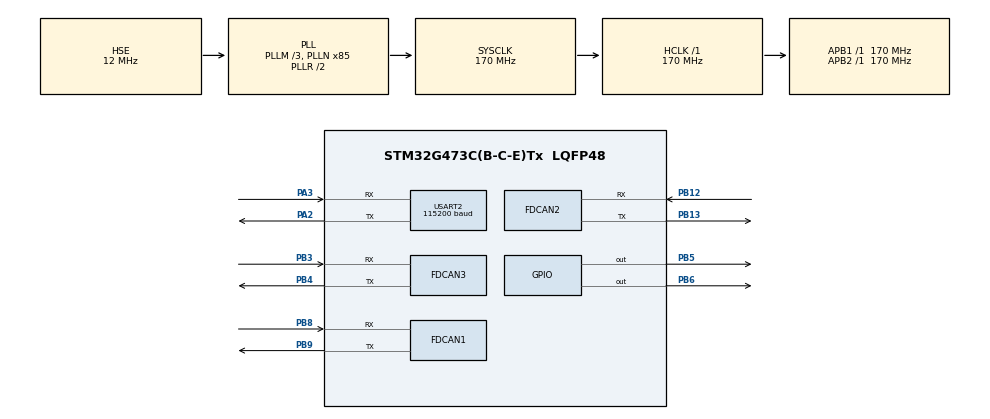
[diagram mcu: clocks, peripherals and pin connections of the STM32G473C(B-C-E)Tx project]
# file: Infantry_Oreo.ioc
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Dma.Request0=USART2_RX
Dma.USART2_RX.0.Direction=DMA_PERIPH_TO_MEMORY
Dma.USART2_RX.0.EventEnable=DISABLE
Dma.USART2_RX.0.Instance=DMA1_Channel3
Dma.USART2_RX.0.MemDataAlignment=DMA_MDATAALIGN_BYTE
Dma.USART2_RX.0.MemInc=DMA_MINC_ENABLE
Dma.USART2_RX.0.Mode=DMA_CIRCULAR
Dma.USART2_RX.0.PeriphDataAlignment=DMA_PDATAALIGN_BYTE
Dma.USART2_RX.0.PeriphInc=DMA_PINC_DISABLE
Dma.USART2_RX.0.Polarity=HAL_DMAMUX_REQ_GEN_RISING
Dma.USART2_RX.0.Priority=DMA_PRIORITY_LOW
Dma.USART2_RX.0.RequestNumber=1
Dma.USART2_RX.0.SignalID=NONE
Dma.USART2_RX.0.SyncEnable=DISABLE
Dma.USART2_RX.0.SyncPolarity=HAL_DMAMUX_SYNC_NO_EVENT
Dma.USART2_RX.0.SyncRequestNumber=1
Dma.USART2_RX.0.SyncSignalID=NONE
FDCAN1.AutoRetransmission=DISABLE
FDCAN1.CalculateBaudRateNominal=1000000
FDCAN1.CalculateTimeQuantumNominal=100.0
FDCAN1.DataPrescaler=2
FDCAN1.DataTimeSeg1=10
FDCAN1.DataTimeSeg2=6
FDCAN1.ExtFiltersNbr=8
FDCAN1.FrameFormat=FDCAN_FRAME_FD_BRS
FDCAN1.Mode=FDCAN_MODE_NORMAL
FDCAN1.NominalPrescaler=17
FDCAN1.NominalTimeSeg1=6
FDCAN1.NominalTimeSeg2=3
FDCAN1.ProtocolException=ENABLE
FDCAN1.StdFiltersNbr=8
FDCAN1.TransmitPause=DISABLE
FDCAN1.TxFifoQueueMode=FDCAN_TX_FIFO_OPERATION
FDCAN2.AutoRetransmission=DISABLE
FDCAN2.CalculateBaudRateNominal=1000000
FDCAN2.CalculateTimeQuantumNominal=100.0
FDCAN2.DataPrescaler=2
FDCAN2.DataTimeSeg1=10
FDCAN2.DataTimeSeg2=6
FDCAN2.ExtFiltersNbr=8
FDCAN2.FrameFormat=FDCAN_FRAME_FD_BRS
FDCAN2.Mode=FDCAN_MODE_NORMAL
FDCAN2.NominalPrescaler=17
FDCAN2.NominalTimeSeg1=6
FDCAN2.NominalTimeSeg2=3
FDCAN2.ProtocolException=ENABLE
FDCAN2.StdFiltersNbr=8
FDCAN2.TransmitPause=DISABLE
FDCAN3.AutoRetransmission=DISABLE
FDCAN3.CalculateBaudRateNominal=1000000
FDCAN3.CalculateTimeQuantumNominal=100.0
FDCAN3.DataPrescaler=2
FDCAN3.DataTimeSeg1=10
FDCAN3.DataTimeSeg2=6
FDCAN3.ExtFiltersNbr=8
FDCAN3.FrameFormat=FDCAN_FRAME_FD_BRS
FDCAN3.Mode=FDCAN_MODE_NORMAL
FDCAN3.NominalPrescaler=17
FDCAN3.NominalTimeSeg1=6
FDCAN3.NominalTimeSeg2=3
FDCAN3.ProtocolException=ENABLE
FDCAN3.StdFiltersNbr=8
FDCAN3.TransmitPause=DISABLE
FREERTOS.INCLUDE_eTaskGetState=1
FREERTOS.INCLUDE_pcTaskGetTaskName=1
FREERTOS.INCLUDE_uxTaskGetStackHighWaterMark=1
FREERTOS.INCLUDE_uxTaskGetStackHighWaterMark2=1
FREERTOS.INCLUDE_vTaskCleanUpResources=1
FREERTOS.INCLUDE_vTaskDelayUntil=1
FREERTOS.INCLUDE_xQueueGetMutexHolder=1
FREERTOS.INCLUDE_xSemaphoreGetMutexHolder=1
FREERTOS.INCLUDE_xTaskAbortDelay=1
FREERTOS.INCLUDE_xTaskGetCurrentTaskHandle=1
FREERTOS.INCLUDE_xTaskGetHandle=1
FREERTOS.MEMORY_ALLOCATION=2
FREERTOS.Tasks01=Init,3,128,Init_Task,As weak,NULL,Dynamic,NULL,NULL;Gimbal,3,128,Gimbal_Task,As weak,NULL,Dynamic,NULL,NULL;BoardCom,3,128,BoardCom_Task,As weak,NULL,Dynamic,NULL,NULL;Chassis,3,512,Chassis_Task,As weak,NULL,Dynamic,NULL,NULL;UI,3,128,UI_Task,As weak,NULL,Dynamic,NULL,NULL;Cap,3,128,Cap_Task,As weak,NULL,Dynamic,NULL,NULL;Monitor,3,128,Monitor_Task,As weak,NULL,Dynamic,NULL,NULL
FREERTOS.configENABLE_FPU=1
FREERTOS.configTOTAL_HEAP_SIZE=15360
Mcu.Family=STM32G4
Mcu.Name=STM32G473C(B-C-E)Tx
Mcu.Package=LQFP48
NVIC.DMA1_Channel3_IRQn=true\:5\:0\:false\:false\:true\:true\:false\:true\:true
NVIC.FDCAN1_IT0_IRQn=true\:5\:0\:false\:false\:true\:true\:true\:true\:true
NVIC.FDCAN2_IT0_IRQn=true\:5\:0\:false\:false\:true\:true\:true\:true\:true
NVIC.FDCAN3_IT0_IRQn=true\:5\:0\:false\:false\:true\:true\:true\:true\:true
NVIC.PVD_PVM_IRQn=true\:5\:0\:false\:false\:true\:true\:true\:true\:true
NVIC.PriorityGroup=NVIC_PRIORITYGROUP_4
NVIC.TIM20_UP_IRQn=true\:15\:0\:false\:false\:true\:false\:false\:true\:true
NVIC.TimeBase=TIM20_UP_IRQn
NVIC.TimeBaseIP=TIM20
NVIC.USART2_IRQn=true\:5\:0\:false\:false\:true\:true\:true\:true\:true
PA13.Mode=Serial_Wire
PA13.Signal=SYS_JTMS-SWDIO
PA14.Mode=Serial_Wire
PA14.Signal=SYS_JTCK-SWCLK
PA2.Mode=Asynchronous
PA2.Signal=USART2_TX
PA3.Mode=Asynchronous
PA3.Signal=USART2_RX
PB12.Mode=FDCAN_Activate
PB12.Signal=FDCAN2_RX
PB13.Mode=FDCAN_Activate
PB13.Signal=FDCAN2_TX
PB3.Mode=FDCAN_Activate
PB3.Signal=FDCAN3_RX
PB4.Mode=FDCAN_Activate
PB4.Signal=FDCAN3_TX
PB5.GPIO_ModeDefaultOutputPP=GPIO_MODE_OUTPUT_PP
PB5.GPIO_PuPd=GPIO_NOPULL
PB5.Signal=GPIO_Output
PB6.GPIO_PuPd=GPIO_PULLDOWN
PB6.Signal=GPIO_Output
PB8-BOOT0.Mode=FDCAN_Activate
PB8-BOOT0.Signal=FDCAN1_RX
PB9.Mode=FDCAN_Activate
PB9.Signal=FDCAN1_TX
PF0-OSC_IN.Mode=HSE-External-Oscillator
PF0-OSC_IN.Signal=RCC_OSC_IN
PF1-OSC_OUT.Mode=HSE-External-Oscillator
PF1-OSC_OUT.Signal=RCC_OSC_OUT
ProjectManager.HeapSize=0x1000
ProjectManager.StackSize=0x2000
ProjectManager.TargetToolchain=MDK-ARM V5.32
RCC.ADC12Freq_Value=170000000
RCC.ADC345Freq_Value=170000000
RCC.AHBFreq_Value=170000000
RCC.APB1Freq_Value=170000000
RCC.APB1TimFreq_Value=170000000
RCC.APB2Freq_Value=170000000
RCC.APB2TimFreq_Value=170000000
RCC.CK48CLockSelection=RCC_USBCLKSOURCE_HSI48
RCC.CortexFreq_Value=170000000
RCC.EXTERNAL_CLOCK_VALUE=12288000
RCC.HCLKFreq_Value=170000000
RCC.HSE_VALUE=12000000
RCC.HSI48_VALUE=48000000
RCC.HSI_VALUE=16000000
RCC.LSE_VALUE=32768
RCC.PLLM=RCC_PLLM_DIV3
RCC.PLLN=85
RCC.PLLQ=RCC_PLLQ_DIV4
RCC.PLLSourceVirtual=RCC_PLLSOURCE_HSE
RCC.SYSCLKFreq_VALUE=170000000
RCC.SYSCLKSource=RCC_SYSCLKSOURCE_PLLCLK
RCC.USBFreq_Value=48000000
RCC.VCOOutputFreq_Value=340000000
SYS.VoltageScaling=SYSCFG_VREFBUF_VOLTAGE_SCALE2
TIM15.PeriodNoDither=9999
TIM15.Prescaler=170-1
TIM3.PeriodNoDither=9999
TIM3.Prescaler=170-1
USART2.BaudRate=115200
USART2.Parity=PARITY_NONE
USART2.VirtualMode-Asynchronous=VM_ASYNC
USART2.WordLength=WORDLENGTH_8B
VP_FREERTOS_VS_CMSIS_V1.Mode=CMSIS_V1
VP_SYS_VS_DBSignals.Mode=DisableDeadBatterySignals
VP_SYS_VS_tim20.Mode=TIM20
VP_TIM15_VS_ClockSourceINT.Mode=Internal
VP_TIM3_VS_ClockSourceINT.Mode=Internal
VREF+.Mode=InternalMode
VREF+.Signal=VREFBUF_OUT
board=custom

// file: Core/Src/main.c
/* USER CODE BEGIN Header */
/**
 ******************************************************************************
 * @file           : main.c
 * @brief          : Main program body
 ******************************************************************************
 * @attention
 *
 * Copyright (c) 2022 STMicroelectronics.
 * All rights reserved.
 *
 * This software is licensed under terms that can be found in the LICENSE file
 * in the root directory of this software component.
 * If no LICENSE file comes with this software, it is provided AS-IS.
 *
 ******************************************************************************
 */
/* USER CODE END Header */
#include "main.h"
#include "cmsis_os.h"
#include "dma.h"
#include "fdcan.h"
#include "tim.h"
#include "usart.h"
#include "gpio.h"

void SystemClock_Config(void);
void MX_FREERTOS_Init(void);

int main(void)
{

  /* MCU Configuration--------------------------------------------------------*/

  /* Reset of all peripherals, Initializes the Flash interface and the Systick. */
  HAL_Init();

  /* Configure the system clock */
  SystemClock_Config();

  /* Initialize all configured peripherals */
  MX_GPIO_Init();
  MX_DMA_Init();
  MX_FDCAN1_Init();
  MX_FDCAN2_Init();
  MX_FDCAN3_Init();
  MX_TIM15_Init();
  MX_USART2_UART_Init();
  MX_TIM3_Init();

  /* Call init function for freertos objects (in freertos.c) */
  MX_FREERTOS_Init();

  /* Start scheduler */
  osKernelStart();

  /* We should never get here as control is now taken by the scheduler */
  /* Infinite loop */
  while (1)
  {

  }
}

void SystemClock_Config(void)
{
  RCC_OscInitTypeDef RCC_OscInitStruct = {0};
  RCC_ClkInitTypeDef RCC_ClkInitStruct = {0};

  /** Configure the main internal regulator output voltage
  */
  HAL_PWREx_ControlVoltageScaling(PWR_REGULATOR_VOLTAGE_SCALE1_BOOST);

  /** Initializes the RCC Oscillators according to the specified parameters
  * in the RCC_OscInitTypeDef structure.
  */
  RCC_OscInitStruct.OscillatorType = RCC_OSCILLATORTYPE_HSE;
  RCC_OscInitStruct.HSEState = RCC_HSE_ON;
  RCC_OscInitStruct.PLL.PLLState = RCC_PLL_ON;
  RCC_OscInitStruct.PLL.PLLSource = RCC_PLLSOURCE_HSE;
  RCC_OscInitStruct.PLL.PLLM = RCC_PLLM_DIV3;
  RCC_OscInitStruct.PLL.PLLN = 85;
  RCC_OscInitStruct.PLL.PLLP = RCC_PLLP_DIV2;
  RCC_OscInitStruct.PLL.PLLQ = RCC_PLLQ_DIV4;
  RCC_OscInitStruct.PLL.PLLR = RCC_PLLR_DIV2;
  if (HAL_RCC_OscConfig(&RCC_OscInitStruct) != HAL_OK)
  {
    Error_Handler();
  }

  /** Initializes the CPU, AHB and APB buses clocks
  */
  RCC_ClkInitStruct.ClockType = RCC_CLOCKTYPE_HCLK|RCC_CLOCKTYPE_SYSCLK
                              |RCC_CLOCKTYPE_PCLK1|RCC_CLOCKTYPE_PCLK2;
  RCC_ClkInitStruct.SYSCLKSource = RCC_SYSCLKSOURCE_PLLCLK;
  RCC_ClkInitStruct.AHBCLKDivider = RCC_SYSCLK_DIV1;
  RCC_ClkInitStruct.APB1CLKDivider = RCC_HCLK_DIV1;
  RCC_ClkInitStruct.APB2CLKDivider = RCC_HCLK_DIV1;

  if (HAL_RCC_ClockConfig(&RCC_ClkInitStruct, FLASH_LATENCY_4) != HAL_OK)
  {
    Error_Handler();
  }
}

void HAL_TIM_PeriodElapsedCallback(TIM_HandleTypeDef *htim)
{
  if (htim->Instance == TIM20) {
    HAL_IncTick();
  }
}

void Error_Handler(void)
{
    __disable_irq();
    while (1) {
    }
}

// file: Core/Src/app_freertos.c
/* USER CODE BEGIN Header */
/**
 ******************************************************************************
 * File Name          : app_freertos.c
 * Description        : Code for freertos applications
 ******************************************************************************
 * @attention
 *
 * Copyright (c) 2022 STMicroelectronics.
 * All rights reserved.
 *
 * This software is licensed under terms that can be found in the LICENSE file
 * in the root directory of this software component.
 * If no LICENSE file comes with this software, it is provided AS-IS.
 *
 ******************************************************************************
 */
/* USER CODE END Header */

#include "FreeRTOS.h"
#include "task.h"
#include "main.h"
#include "cmsis_os.h"

/* USER CODE BEGIN Includes */
#include "app_chassis.h"
#include "app_power.h"
#include "protocol_board.h"
#include "config_ctrl.h"
#include "app_gimbal.h"
#include "periph_cap.h"

/* USER CODE END Includes */

osThreadId InitHandle;
osThreadId GimbalHandle;
osThreadId BoardComHandle;
osThreadId ChassisHandle;
osThreadId UIHandle;
osThreadId CapHandle;
osThreadId MonitorHandle;

void Init_Task(void const * argument);
void Gimbal_Task(void const * argument);
void BoardCom_Task(void const * argument);
void Chassis_Task(void const * argument);
void UI_Task(void const * argument);
void Cap_Task(void const * argument);
void Monitor_Task(void const * argument);

void MX_FREERTOS_Init(void); /* (MISRA C 2004 rule 8.1) */

/* GetIdleTaskMemory prototype (linked to static allocation support) */
void vApplicationGetIdleTaskMemory( StaticTask_t **ppxIdleTaskTCBBuffer, StackType_t **ppxIdleTaskStackBuffer, uint32_t *pulIdleTaskStackSize );

/* USER CODE BEGIN GET_IDLE_TASK_MEMORY */
static StaticTask_t xIdleTaskTCBBuffer;
static StackType_t xIdleStack[configMINIMAL_STACK_SIZE];

void vApplicationGetIdleTaskMemory(StaticTask_t** ppxIdleTaskTCBBuffer, StackType_t** ppxIdleTaskStackBuffer, uint32_t* pulIdleTaskStackSize) {
    *ppxIdleTaskTCBBuffer = &xIdleTaskTCBBuffer;
    *ppxIdleTaskStackBuffer = &xIdleStack[0];
    *pulIdleTaskStackSize = configMINIMAL_STACK_SIZE;
    /* place for user code */
}
/* USER CODE END GET_IDLE_TASK_MEMORY */

void MX_FREERTOS_Init(void) {

  /* Create the thread(s) */
  /* definition and creation of Init */
  osThreadDef(Init, Init_Task, osPriorityRealtime, 0, 128);
  InitHandle = osThreadCreate(osThread(Init), NULL);

  /* definition and creation of Gimbal */
  osThreadDef(Gimbal, Gimbal_Task, osPriorityRealtime, 0, 128);
  GimbalHandle = osThreadCreate(osThread(Gimbal), NULL);

  /* definition and creation of BoardCom */
  osThreadDef(BoardCom, BoardCom_Task, osPriorityRealtime, 0, 128);
  BoardComHandle = osThreadCreate(osThread(BoardCom), NULL);

  /* definition and creation of Chassis */
  osThreadDef(Chassis, Chassis_Task, osPriorityRealtime, 0, 512);
  ChassisHandle = osThreadCreate(osThread(Chassis), NULL);

  /* definition and creation of UI */
  osThreadDef(UI, UI_Task, osPriorityRealtime, 0, 128);
  UIHandle = osThreadCreate(osThread(UI), NULL);

  /* definition and creation of Cap */
  osThreadDef(Cap, Cap_Task, osPriorityRealtime, 0, 128);
  CapHandle = osThreadCreate(osThread(Cap), NULL);

  /* definition and creation of Monitor */
  osThreadDef(Monitor, Monitor_Task, osPriorityRealtime, 0, 128);
  MonitorHandle = osThreadCreate(osThread(Monitor), NULL);

}

__weak void Init_Task(void const * argument)
{
    for (;;) {
        osDelay(1);
    }
}

__weak void Gimbal_Task(void const * argument)
{
    for (;;) {
        osDelay(1);
    }
}

__weak void BoardCom_Task(void const * argument)
{
  for(;;)
  {
    osDelay(1);
  }
}

__weak void Chassis_Task(void const * argument)
{
    for (;;) {
        osDelay(1);
    }
}

__weak void UI_Task(void const * argument)
{
  for(;;)
  {
    osDelay(1);
  }
}

__weak void Cap_Task(void const * argument)
{
  for(;;)
  {
    osDelay(1);
  }
}

__weak void Monitor_Task(void const * argument)
{
  for(;;)
  {
    osDelay(1);
  }
}
